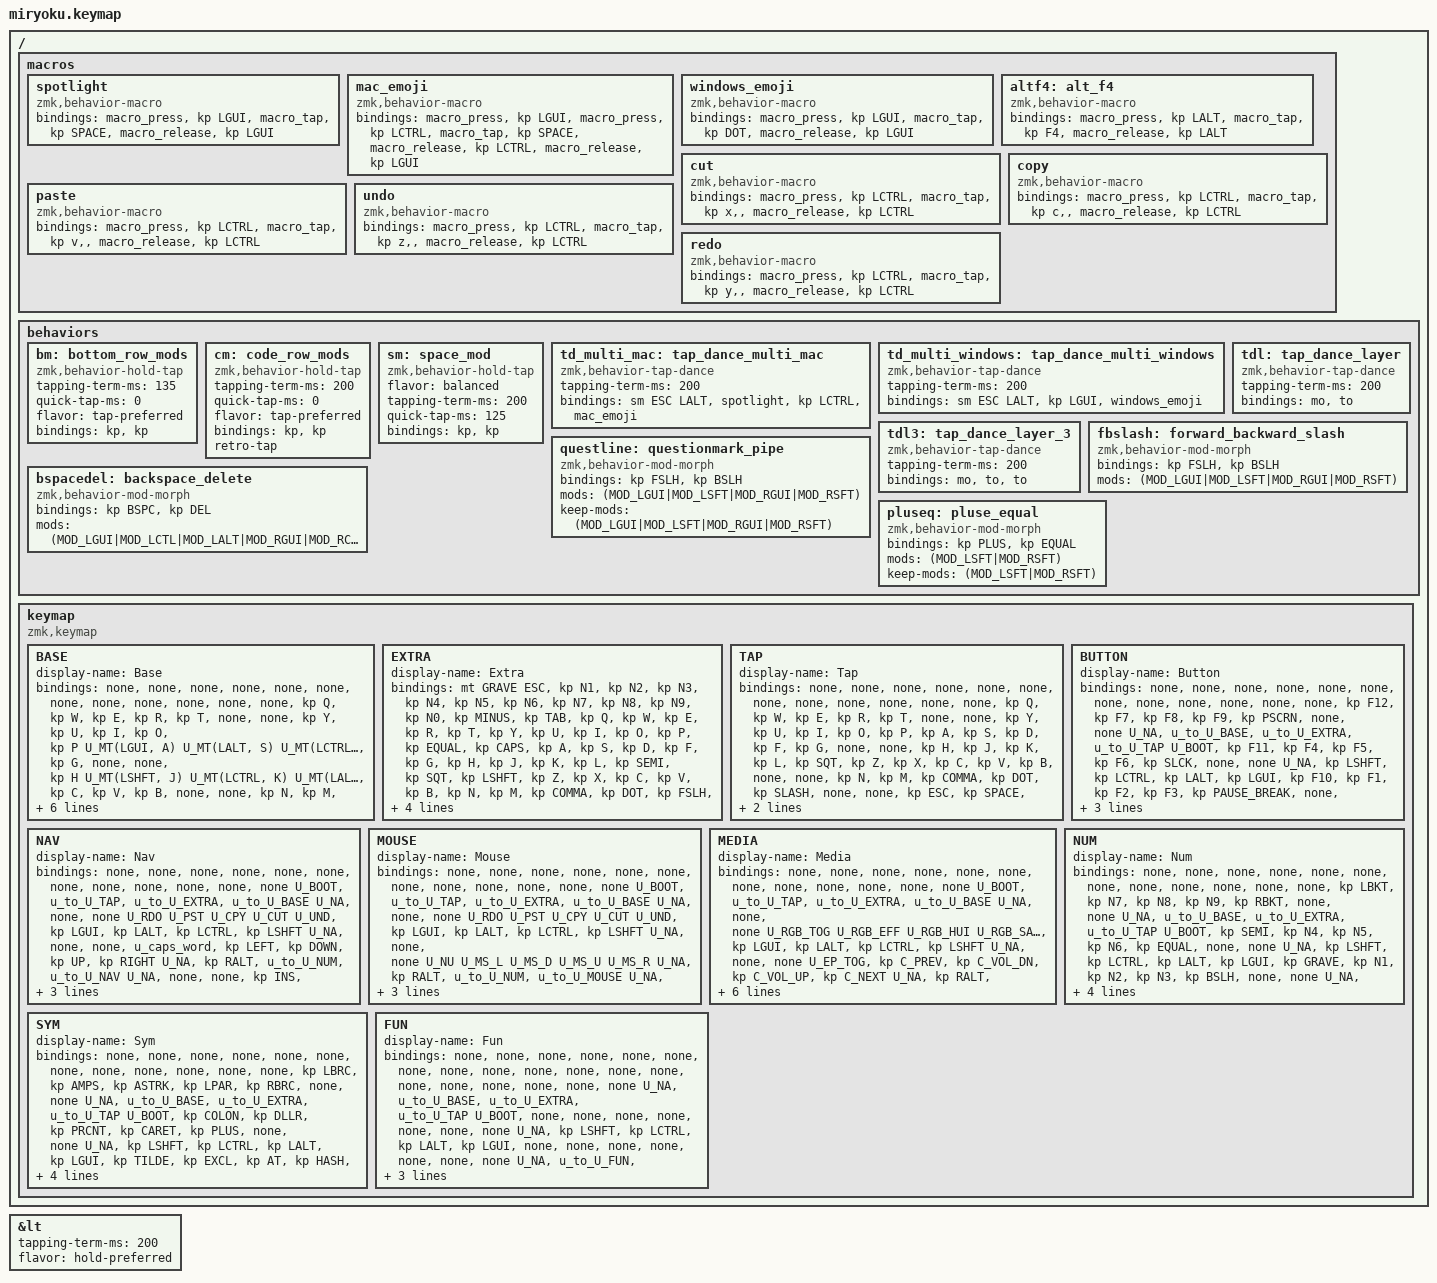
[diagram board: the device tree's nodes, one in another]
#include <behaviors.dtsi>
#include <dt-bindings/zmk/keys.h>
#include <dt-bindings/zmk/bt.h>
#include <dt-bindings/zmk/outputs.h>
#include <dt-bindings/zmk/backlight.h>
#include <dt-bindings/zmk/rgb.h>
#include <dt-bindings/zmk/ext_power.h>

#define ZMK_POINTING_DEFAULT_MOVE_VAL 600
#define ZMK_POINTING_DEFAULT_SCRL_VAL 10

#include <dt-bindings/zmk/pointing.h>

#define U_BASE   0
#define U_EXTRA  1
#define U_TAP    2
#define U_BUTTON 3
#define U_NAV    4
#define U_MOUSE  5
#define U_MEDIA  6
#define U_NUM    7
#define U_SYM    8
#define U_FUN    9

//Shift Functions
#define U_RGB_TOG &rgb_ug RGB_TOG
#define U_RGB_EFF &rgb_ug RGB_EFF
#define U_RGB_HUI &rgb_ug RGB_HUI
#define U_RGB_SAI &rgb_ug RGB_SAI
#define U_RGB_BRI &rgb_ug RGB_BRI
#define U_EP_TOG &ext_power EP_TOG

// Mousekeys
#define U_BTN1 &mkp MB1
#define U_BTN2 &mkp MB2
#define U_BTN3 &mkp MB3

#define U_MS_D &kp KP_N2
#define U_MS_L &kp KP_N4
#define U_MS_R &kp KP_N6
#define U_MS_U &kp KP_N8
#define U_WH_D U_NU
#define U_WH_L U_NU
#define U_WH_R U_NU
#define U_WH_U U_NU

// Behavior Overrides
&lt {
    tapping-term-ms = <200>;
    flavor = "hold-preferred";
};

/ {
    macros {
        spotlight: spotlight {
            compatible = "zmk,behavior-macro";
            #binding-cells = <0>;
            bindings = <&macro_press &kp LGUI>, <&macro_tap &kp SPACE>, <&macro_release &kp LGUI>; 
        };

        // Emoji
        mac_emoji: mac_emoji {
            compatible = "zmk,behavior-macro";
            #binding-cells = <0>;
            bindings = <&macro_press &kp LGUI>, <&macro_press &kp LCTRL>, <&macro_tap &kp SPACE>, <&macro_release &kp LCTRL>, <&macro_release &kp LGUI>; 
        };

        windows_emoji: windows_emoji {
            compatible = "zmk,behavior-macro";
            #binding-cells = <0>;
            bindings = <&macro_press &kp LGUI>, <&macro_tap &kp DOT>, <&macro_release &kp LGUI>; 
        };

        altf4: alt_f4 {
            compatible = "zmk,behavior-macro";
            #binding-cells = <0>;
            bindings = <&macro_press &kp LALT>, <&macro_tap &kp F4>, <&macro_release &kp LALT>; 
        };

        cut: cut {
            compatible = "zmk,behavior-macro";
            #binding-cells = <0>;
            bindings = <&macro_press &kp LCTRL>, <&macro_tap &kp x, <&macro_release &kp LCTRL>; 
        };

        copy: copy {
            compatible = "zmk,behavior-macro";
            #binding-cells = <0>;
            bindings = <&macro_press &kp LCTRL>, <&macro_tap &kp c, <&macro_release &kp LCTRL>; 
        };

        paste: paste {
            compatible = "zmk,behavior-macro";
            #binding-cells = <0>;
            bindings = <&macro_press &kp LCTRL>, <&macro_tap &kp v, <&macro_release &kp LCTRL>; 
        };

        undo: undo {
            compatible = "zmk,behavior-macro";
            #binding-cells = <0>;
            bindings = <&macro_press &kp LCTRL>, <&macro_tap &kp z, <&macro_release &kp LCTRL>; 
        };

        redo: redo {
            compatible = "zmk,behavior-macro";
            #binding-cells = <0>;
            bindings = <&macro_press &kp LCTRL>, <&macro_tap &kp y, <&macro_release &kp LCTRL>; 
        };
    };

    behaviors {
        bm: bottom_row_mods {
            compatible = "zmk,behavior-hold-tap";
            #binding-cells = <2>;
            tapping-term-ms = <135>;
            quick-tap-ms = <0>;
            flavor = "tap-preferred";
            bindings = <&kp>, <&kp>;
        };

        cm: code_row_mods {
            compatible = "zmk,behavior-hold-tap";
            #binding-cells = <2>;
            tapping-term-ms = <200>;
            quick-tap-ms = <0>;
            flavor = "tap-preferred";
            bindings = <&kp>, <&kp>;
            retro-tap;
        };

        sm: space_mod {
            compatible = "zmk,behavior-hold-tap";
            #binding-cells = <2>;
            flavor = "balanced";
            tapping-term-ms = <200>;
            quick-tap-ms = <125>;
            bindings = <&kp>, <&kp>;
        };

        td_multi_mac: tap_dance_multi_mac {
            compatible = "zmk,behavior-tap-dance";
            #binding-cells = <0>;
            tapping-term-ms = <200>;
            bindings = <&sm ESC LALT>, <&spotlight>, <&kp LCTRL>, <&mac_emoji>;
        };

        td_multi_windows: tap_dance_multi_windows {
            compatible = "zmk,behavior-tap-dance";
            #binding-cells = <0>;
            tapping-term-ms = <200>;
            bindings = <&sm ESC LALT>, <&kp LGUI>, <&windows_emoji>;
        };

        tdl: tap_dance_layer {
            compatible = "zmk,behavior-tap-dance";
            #binding-cells = <2>;
            tapping-term-ms = <200>;
            bindings = <&mo>, <&to>;
        };

        tdl3: tap_dance_layer_3 {
            compatible = "zmk,behavior-tap-dance";
            #binding-cells = <3>;
            tapping-term-ms = <200>;
            bindings = <&mo>, <&to>, <&to>;
        };

        fbslash: forward_backward_slash {
            compatible = "zmk,behavior-mod-morph";
            #binding-cells = <0>;
            bindings = <&kp FSLH>, <&kp BSLH>;
            mods = <(MOD_LGUI|MOD_LSFT|MOD_RGUI|MOD_RSFT)>;
        }

        questline: questionmark_pipe {
            compatible = "zmk,behavior-mod-morph";
            #binding-cells = <0>;
            bindings = <&kp FSLH>, <&kp BSLH>;
            mods = <(MOD_LGUI|MOD_LSFT|MOD_RGUI|MOD_RSFT)>;
            keep-mods = <(MOD_LGUI|MOD_LSFT|MOD_RGUI|MOD_RSFT)>; 
        }

        bspacedel: backspace_delete {
            compatible = "zmk,behavior-mod-morph";
            #binding-cells = <0>;
            bindings = <&kp BSPC>, <&kp DEL>;
            mods = <(MOD_LGUI|MOD_LCTL|MOD_LALT|MOD_RGUI|MOD_RCTL|MOD_RALT)>;
        }

        pluseq: pluse_equal {
            compatible = "zmk,behavior-mod-morph";
            #binding-cells = <0>;
            bindings = <&kp PLUS>, <&kp EQUAL>;
            mods = <(MOD_LSFT|MOD_RSFT)>;
            keep-mods = <(MOD_LSFT|MOD_RSFT)>;
        }
    };
    
    keymap {
        compatible = "zmk,keymap";

        BASE {
            display-name = "Base";
            bindings = <
            // -------------------------------------------------------------------------------------------------------------------------------------------------------
            // |   1      |    2   |    3    |    4          |  5      |    `        | || |   -          |      6         |   7         |    8    |   9     |   0    |
            // |   Q      |    W   |    E    |    R          |  T      |   GUI       | || |   + - =      |      Y         |   U         |    I    |   O     |   P    |
            // |   A      |    S   |    D    |    F          |  G      |   ESC       | || |    '         |      H         |   J         |    K    |   L     |   ;    | 
            // |   Z      |    X   |    C    |    V          |  B      |  NUMBER     | || |   NUMBER     |      N         |   M         |    ,    |   .     | ? - |  |                                  
            // |  CTRL    |  TAB   |   ALT   |  SHIFT - CAPS | SPACE   |   FUN       | || |   FUN        |     NAV        |  BSPC-DEL   |   "["   |  "]"    |  / - \ |
                &none             &none         &none              &none              &none              &none &none &none            &none             &none             &none           &none
                &kp Q             &kp W         &kp E              &kp R              &kp T              &none &none &kp Y            &kp U             &kp I             &kp O           &kp P
                U_MT(LGUI, A)     U_MT(LALT, S) U_MT(LCTRL, D)     U_MT(LSHFT, F)     &kp G              &none &none &kp H            U_MT(LSHFT, J)    U_MT(LCTRL, K)    U_MT(LALT, L)   U_MT(LGUI, SQT)
                U_LT(U_BUTTON, Z) U_MT(RALT, X) &kp C              &kp V              &kp B              &none &none &kp N            &kp M             &kp COMMA         U_MT(RALT, DOT) U_LT(U_BUTTON, SLASH)
                &none             &none         U_LT(U_MEDIA, ESC) U_LT(U_NAV, SPACE) U_LT(U_MOUSE, TAB) &none &none U_LT(U_SYM, RET) U_LT(U_NUM, BSPC) &U_LT(U_FUN, DEL) &none           &none
            >;
        };

        EXTRA {
            display-name = "Extra";
            bindings = <
            // ---------------------------------------------------------------------------------------------------------------------------------
            // | ` - ESC |   1    |    2   |    3    |    4    |  5          | || |    6        |   7    |    8    |   9    |   0    |    -    |
            // |  TAB    |   Q    |    W   |    E    |    R    |  T          | || |    Y        |   U    |    I    |   O    |   P    |    =    |
            // |  CAPS   |   A    |    S   |    D    |    F    |  G          | || |    H        |   J    |    K    |   L    |   ;    |    '    |
            // |  SHIFT  |   Z    |    X   |    C    |    V    |  B          | || |    N        |   M    |    ,    |   .    |   /    |    \    |
            // |  CTRL   |  GUI   |   ALT  |  SPACE  |    `    | FUN         | || |    FUN      |  FUN   |   "["   |  "]"   |  BSPC  | DELETE  |
            &mt GRAVE ESC &kp N1   &kp N2   &kp N3    &kp N4    &kp N5            &kp N6        &kp N7    &kp N8    &kp N9   &kp N0   &kp MINUS 
                &kp TAB   &kp Q    &kp W    &kp E     &kp R     &kp T             &kp Y         &kp U     &kp I     &kp O    &kp P    &kp EQUAL
                &kp CAPS  &kp A    &kp S    &kp D     &kp F     &kp G             &kp H         &kp J     &kp K     &kp L    &kp SEMI &kp SQT
                &kp LSHFT &kp Z    &kp X    &kp C     &kp V     &kp B             &kp N         &kp M     &kp COMMA &kp DOT  &kp FSLH &kp BSLH
                &kp LCTRL &kp LGUI &kp LALT &kp SPACE &kp GRAVE &tdl FUN FUN      &tdl FUN FUN  &kp SPACE &kp LBKT  &kp RBKT &kp BSPC &kp DEL
            >;
        };

        TAP {
            display-name = "Tap";
            bindings = <
            // -------------------------------------------------------------------------------------------------------------------------------------------------------
            // |   1      |    2   |    3    |    4          |  5      |    `        | || |   -          |      6         |   7         |    8    |   9     |   0    |
            // |   Q      |    W   |    E    |    R          |  T      |   GUI       | || |   + - =      |      Y         |   U         |    I    |   O     |   P    |
            // |   A      |    S   |    D    |    F          |  G      |   ESC       | || |    '         |      H         |   J         |    K    |   L     |   ;    | 
            // |   Z      |    X   |    C    |    V          |  B      |  NUMBER     | || |   NUMBER     |      N         |   M         |    ,    |   .     | ? - |  |                                  
            // |  CTRL    |  TAB   |   ALT   |  SHIFT - CAPS | SPACE   |   FUN       | || |   FUN        |     NAV        |  BSPC-DEL   |   "["   |  "]"    |  / - \ |
                &none &none &none   &none &none &none &none &none            &none             &none             &none           &none
                &kp Q &kp W &kp E   &kp R     &kp T   &none &none &kp Y   &kp U    &kp I     &kp O   &kp P
                &kp A &kp S &kp D   &kp F     &kp G   &none &none &kp H   &kp J    &kp K     &kp L   &kp SQT
                &kp Z &kp X &kp C   &kp V     &kp B   &none &none &kp N   &kp M    &kp COMMA &kp DOT &kp SLASH
                &none &none &kp ESC &kp SPACE &kp TAB &none &none &kp RET &kp BSPC &kp DEL   &none   &none
            >;
        };

        BUTTON {
            display-name = "Button";
            bindings = <
            // -------------------------------------------------------------------------------------------------------------------------------------------------------
            // |   1      |    2   |    3    |    4          |  5      |    `        | || |   -          |      6         |   7         |    8    |   9     |   0    |
            // |   Q      |    W   |    E    |    R          |  T      |   GUI       | || |   + - =      |      Y         |   U         |    I    |   O     |   P    |
            // |   A      |    S   |    D    |    F          |  G      |   ESC       | || |    '         |      H         |   J         |    K    |   L     |   ;    | 
            // |   Z      |    X   |    C    |    V          |  B      |  NUMBER     | || |   NUMBER     |      N         |   M         |    ,    |   .     | ? - |  |                                  
            // |  CTRL    |  TAB   |   ALT   |  SHIFT - CAPS | SPACE   |   FUN       | || |   FUN        |     NAV        |  BSPC-DEL   |   "["   |  "]"    |  / - \ |
                &none     &none    &none     &none           &none     &none               &none     &none    &none     &none           &none     &none
                &kp F12 &kp F7 &kp F8    &kp F9    &kp PSCRN       &none &none U_NA &u_to_U_BASE &u_to_U_EXTRA &u_to_U_TAP U_BOOT
                &kp F11 &kp F4 &kp F5    &kp F6    &kp SLCK        &none &none U_NA &kp LSHFT    &kp LCTRL     &kp LALT    &kp LGUI
                &kp F10 &kp F1 &kp F2    &kp F3    &kp PAUSE_BREAK &none &none U_NA &u_to_U_FUN  &u_to_U_MEDIA &kp RALT    U_NA
                U_NP    U_NP   &kp K_APP &kp SPACE &kp TAB         &none &none U_NA U_NA         U_NA          U_NP        U_NP
            >;
        };

        
        NAV {
            display-name = "Nav";
            bindings = <
            // -------------------------------------------------------------------------------------------------------------------------------------------------------
            // |   1      |    2   |    3    |    4          |  5      |    `        | || |   -          |      6         |   7         |    8    |   9     |   0    |
            // |   Q      |    W   |    E    |    R          |  T      |   GUI       | || |   + - =      |      Y         |   U         |    I    |   O     |   P    |
            // |   A      |    S   |    D    |    F          |  G      |   ESC       | || |    '         |      H         |   J         |    K    |   L     |   ;    | 
            // |   Z      |    X   |    C    |    V          |  B      |  NUMBER     | || |   NUMBER     |      N         |   M         |    ,    |   .     | ? - |  |                                  
            // |  CTRL    |  TAB   |   ALT   |  SHIFT - CAPS | SPACE   |   FUN       | || |   FUN        |     NAV        |  BSPC-DEL   |   "["   |  "]"    |  / - \ |
                &none     &none    &none     &none           &none     &none               &none     &none    &none     &none           &none     &none
                U_BOOT   &u_to_U_TAP &u_to_U_EXTRA &u_to_U_BASE U_NA &none &none U_RDO        U_PST    U_CPY     U_CUT     U_UND
                &kp LGUI &kp LALT    &kp LCTRL     &kp LSHFT    U_NA &none &none &u_caps_word &kp LEFT &kp DOWN  &kp UP    &kp RIGHT 
                U_NA     &kp RALT    &u_to_U_NUM   &u_to_U_NAV  U_NA &none &none &kp INS      &kp HOME &kp PG_DN &kp PG_UP &kp END
                U_NP     U_NP        U_NA          U_NA         U_NA &none &none &kp RET      &kp BSPC &kp DEL   U_NP      U_NP 
            >;
        };

        MOUSE {
            display-name = "Mouse";
            bindings = <
            // -------------------------------------------------------------------------------------------------------------------------------------------------------
            // |   1      |    2   |    3    |    4          |  5      |    `        | || |   -          |      6         |   7         |    8    |   9     |   0    |
            // |   Q      |    W   |    E    |    R          |  T      |   GUI       | || |   + - =      |      Y         |   U         |    I    |   O     |   P    |
            // |   A      |    S   |    D    |    F          |  G      |   ESC       | || |    '         |      H         |   J         |    K    |   L     |   ;    | 
            // |   Z      |    X   |    C    |    V          |  B      |  NUMBER     | || |   NUMBER     |      N         |   M         |    ,    |   .     | ? - |  |                                  
            // |  CTRL    |  TAB   |   ALT   |  SHIFT - CAPS | SPACE   |   FUN       | || |   FUN        |     NAV        |  BSPC-DEL   |   "["   |  "]"    |  / - \ |
                &none     &none    &none     &none           &none     &none               &none     &none    &none     &none           &none     &none
                U_BOOT   &u_to_U_TAP &u_to_U_EXTRA &u_to_U_BASE  U_NA &none &none U_RDO  U_PST  U_CPY  U_CUT  U_UND
                &kp LGUI &kp LALT    &kp LCTRL     &kp LSHFT     U_NA &none &none U_NU   U_MS_L U_MS_D U_MS_U U_MS_R 
                U_NA     &kp RALT    &u_to_U_NUM   &u_to_U_MOUSE U_NA &none &none U_NU   U_WH_L U_WH_D U_WH_U U_WH_R
                U_NP     U_NP        U_NA          U_NA          U_NA &none &none U_BTN2 U_BTN1 U_BTN3 U_NP   U_NP 
            >;
        };

        MEDIA {
            display-name = "Media";
            bindings = <
            // -------------------------------------------------------------------------------------------------------------------------------------------------------
            // |   1      |    2   |    3    |    4          |  5      |    `        | || |   -          |      6         |   7         |    8    |   9     |   0    |
            // |   Q      |    W   |    E    |    R          |  T      |   GUI       | || |   + - =      |      Y         |   U         |    I    |   O     |   P    |
            // |   A      |    S   |    D    |    F          |  G      |   ESC       | || |    '         |      H         |   J         |    K    |   L     |   ;    | 
            // |   Z      |    X   |    C    |    V          |  B      |  NUMBER     | || |   NUMBER     |      N         |   M         |    ,    |   .     | ? - |  |                                  
            // |  CTRL    |  TAB   |   ALT   |  SHIFT - CAPS | SPACE   |   FUN       | || |   FUN        |     NAV        |  BSPC-DEL   |   "["   |  "]"    |  / - \ |
                &none     &none    &none     &none           &none     &none               &none     &none    &none     &none           &none     &none
                U_BOOT   &u_to_U_TAP &u_to_U_EXTRA &u_to_U_BASE  U_NA &none  &none U_RGB_TOG  U_RGB_EFF   U_RGB_HUI    U_RGB_SAI    U_RGB_BRI
                &kp LGUI &kp LALT    &kp LCTRL     &kp LSHFT     U_NA &none  &none U_EP_TOG   &kp C_PREV  &kp C_VOL_DN &kp C_VOL_UP &kp C_NEXT
                U_NA     &kp RALT    &u_to_U_FUN   &u_to_U_MEDIA U_NA &none  &none &u_out_tog &u_bt_sel_0 &u_bt_sel_1  &u_bt_sel_2  &u_bt_sel_3
                U_NP     U_NP        U_NA          U_NA          U_NA &none  &none &kp C_STOP &kp C_PP    &kp C_MUTE   U_NP         U_NP
            >;
        };

        NUM {
            display-name = "Num";
            bindings = <
            // -------------------------------------------------------------------------------------------------------------------------------------------------------
            // |   1      |    2   |    3    |    4          |  5      |    `        | || |   -          |      6         |   7         |    8    |   9     |   0    |
            // |   Q      |    W   |    E    |    R          |  T      |   GUI       | || |   + - =      |      Y         |   U         |    I    |   O     |   P    |
            // |   A      |    S   |    D    |    F          |  G      |   ESC       | || |    '         |      H         |   J         |    K    |   L     |   ;    | 
            // |   Z      |    X   |    C    |    V          |  B      |  NUMBER     | || |   NUMBER     |      N         |   M         |    ,    |   .     | ? - |  |                                  
            // |  CTRL    |  TAB   |   ALT   |  SHIFT - CAPS | SPACE   |   FUN       | || |   FUN        |     NAV        |  BSPC-DEL   |   "["   |  "]"    |  / - \ |
                &none     &none    &none     &none           &none     &none               &none     &none    &none     &none           &none     &none
                &kp LBKT  &kp N7 &kp N8  &kp N9 &kp RBKT  &none &none U_NA &u_to_U_BASE &u_to_U_EXTRA &u_to_U_TAP U_BOOT
                &kp SEMI  &kp N4 &kp N5  &kp N6 &kp EQUAL &none &none U_NA &kp LSHFT    &kp LCTRL     &kp LALT    &kp LGUI
                &kp GRAVE &kp N1 &kp N2  &kp N3 &kp BSLH  &none &none U_NA &u_to_U_NUM  &u_to_U_NAV   &kp RALT    U_NA
                U_NP      U_NP   &kp DOT &kp N0 &kp MINUS &none &none U_NA U_NA         U_NA          U_NP        U_NP
            >;
        };

        SYM {
            display-name = "Sym";
            bindings = <
            // -------------------------------------------------------------------------------------------------------------------------------------------------------
            // |   1      |    2   |    3    |    4          |  5      |    `        | || |   -          |      6         |   7         |    8    |   9     |   0    |
            // |   Q      |    W   |    E    |    R          |  T      |   GUI       | || |   + - =      |      Y         |   U         |    I    |   O     |   P    |
            // |   A      |    S   |    D    |    F          |  G      |   ESC       | || |    '         |      H         |   J         |    K    |   L     |   ;    | 
            // |   Z      |    X   |    C    |    V          |  B      |  NUMBER     | || |   NUMBER     |      N         |   M         |    ,    |   .     | ? - |  |                                  
            // |  CTRL    |  TAB   |   ALT   |  SHIFT - CAPS | SPACE   |   FUN       | || |   FUN        |     NAV        |  BSPC-DEL   |   "["   |  "]"    |  / - \ |
                &none     &none    &none     &none           &none     &none               &none     &none    &none     &none           &none     &none
                &kp LBRC  &kp AMPS &kp ASTRK &kp LPAR  &kp RBRC  &none &none U_NA &u_to_U_BASE &u_to_U_EXTRA &u_to_U_TAP U_BOOT
                &kp COLON &kp DLLR &kp PRCNT &kp CARET &kp PLUS  &none &none U_NA &kp LSHFT    &kp LCTRL     &kp LALT    &kp LGUI
                &kp TILDE &kp EXCL &kp AT    &kp HASH  &kp PIPE  &none &none U_NA &u_to_U_SYM  &u_to_U_MOUSE &kp RALT    U_NA
                U_NP      U_NP     &kp LPAR  &kp RPAR  &kp UNDER &none &none U_NA U_NA         U_NA          U_NP        U_NP
            >;
        };

        FUN {
            display-name = "Fun";
            bindings = <
            // -------------------------------------------------------------------------------------------------------------------------------------------------------
            // |   1      |    2   |    3    |    4          |  5      |    `        | || |   -          |      6         |   7         |    8    |   9     |   0    |
            // |   Q      |    W   |    E    |    R          |  T      |   GUI       | || |   + - =      |      Y         |   U         |    I    |   O     |   P    |
            // |   A      |    S   |    D    |    F          |  G      |   ESC       | || |    '         |      H         |   J         |    K    |   L     |   ;    | 
            // |   Z      |    X   |    C    |    V          |  B      |  NUMBER     | || |   NUMBER     |      N         |   M         |    ,    |   .     | ? - |  |                                  
            // |  CTRL    |  TAB   |   ALT   |  SHIFT - CAPS | SPACE   |   FUN       | || |   FUN        |     NAV        |  BSPC-DEL   |   "["   |  "]"    |  / - \ |
                &none     &none    &none     &none           &none     &none               &none     &none    &none     &none           &none     &none
                &none     &none    &none     &none           &none     &none               &none U_NA &u_to_U_BASE &u_to_U_EXTRA &u_to_U_TAP U_BOOT
                &none     &none    &none     &none           &none     &none               &none U_NA &kp LSHFT    &kp LCTRL     &kp LALT    &kp LGUI
                &none     &none    &none     &none           &none     &none               &none U_NA &u_to_U_FUN  &u_to_U_MEDIA &kp RALT    U_NA
                &none     &none    &none     &none           &none     &none               &none U_NA U_NA         U_NA          U_NP        U_NP
            >;
        };
    };
};
